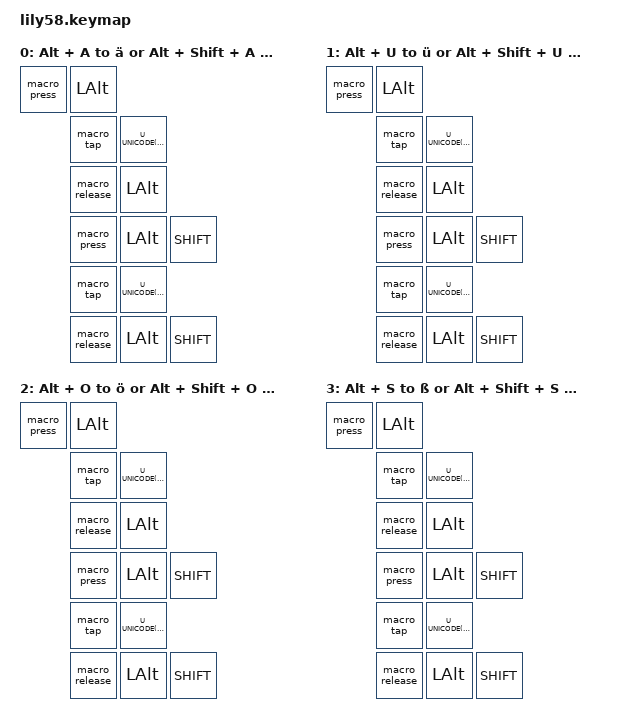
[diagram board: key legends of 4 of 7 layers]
/*
 * Copyright (c) 2020 The ZMK Contributors
 *
 * SPDX-License-Identifier: MIT
 */

#include <behaviors.dtsi>
#include <dt-bindings/zmk/keys.h>
#include <dt-bindings/zmk/bt.h>
#include <dt-bindings/zmk/ext_power.h>

/ {
    keymap {
        compatible = "zmk,keymap";

// Makro-Definition hier:
        a_alt_macro {
            label = "Alt + A to ä or Alt + Shift + A to Ä";
            compatible = "zmk,behavior-macro";
            wait-ms = <40>;
            tap-ms = <40>;
            bindings
                // Wenn nur Alt gedrückt wird
                = <&macro_press   &kp LALT>  
                , <&macro_tap     &kp U_UNICODE(0x00E4)>  // Unicode für kleines ä (Alt + A)
                , <&macro_release &kp LALT>

                // Wenn Alt + Shift gedrückt werden
                , <&macro_press   &kp LALT &kp SHIFT>
                , <&macro_tap     &kp U_UNICODE(0x00C4)>  // Unicode für großes Ä (Alt + Shift + A)
                , <&macro_release &kp LALT &kp SHIFT>;
        };

        // Makro für Alt + U (ü) und Alt + Shift + U (Ü)
        u_alt_macro {
            label = "Alt + U to ü or Alt + Shift + U to Ü";
            compatible = "zmk,behavior-macro";
            wait-ms = <40>;
            tap-ms = <40>;
            bindings
                // Wenn nur Alt gedrückt wird
                = <&macro_press   &kp LALT>  
                , <&macro_tap     &kp U_UNICODE(0x00FC)>  // Unicode für kleines ü (Alt + U)
                , <&macro_release &kp LALT>

                // Wenn Alt + Shift gedrückt werden
                , <&macro_press   &kp LALT &kp SHIFT>
                , <&macro_tap     &kp U_UNICODE(0x00DC)>  // Unicode für großes Ü (Alt + Shift + U)
                , <&macro_release &kp LALT &kp SHIFT>;
        };

        // Makro für Alt + O (ö) und Alt + Shift + O (Ö)
        o_alt_macro {
            label = "Alt + O to ö or Alt + Shift + O to Ö";
            compatible = "zmk,behavior-macro";
            wait-ms = <40>;
            tap-ms = <40>;
            bindings
                // Wenn nur Alt gedrückt wird
                = <&macro_press   &kp LALT>  
                , <&macro_tap     &kp U_UNICODE(0x00F6)>  // Unicode für kleines ö (Alt + O)
                , <&macro_release &kp LALT>

                // Wenn Alt + Shift gedrückt werden
                , <&macro_press   &kp LALT &kp SHIFT>
                , <&macro_tap     &kp U_UNICODE(0x00D6)>  // Unicode für großes Ö (Alt + Shift + O)
                , <&macro_release &kp LALT &kp SHIFT>;
        };

        // Makro für Alt + S (ß) und Alt + Shift + S (ẞ)
        s_alt_macro {
            label = "Alt + S to ß or Alt + Shift + S to ẞ";
            compatible = "zmk,behavior-macro";
            wait-ms = <40>;
            tap-ms = <40>;
            bindings
                // Wenn nur Alt gedrückt wird
                = <&macro_press   &kp LALT>  
                , <&macro_tap     &kp U_UNICODE(0x00DF)>  // Unicode für ß (Alt + S)
                , <&macro_release &kp LALT>

                // Wenn Alt + Shift gedrückt werden
                , <&macro_press   &kp LALT &kp SHIFT>
                , <&macro_tap     &kp U_UNICODE(0x1E9E)>  // Unicode für großes ẞ (Alt + Shift + S)
                , <&macro_release &kp LALT &kp SHIFT>;
        };

        default_layer {
            // ------------------------------------------------------------------------------------------------------------
            // |  ESC  |  1  |  2  |  3   |  4   |  5   |                   |  6   |  7    |  8    |  9   |   0   |   `   |
            // |  TAB  |  Q  |  W  |  E   |  R   |  T   |                   |  Y   |  U    |  I    |  O   |   P   |   -   |
            // |  CTRL |  A  |  S  |  D   |  F   |  G   |                   |  H   |  J    |  K    |  L   |   ;   |   '   |
            // | SHIFT |  Z  |  X  |  C   |  V   |  B   |   "["  |  |  "]"  |  N   |  M    |  ,    |  .   |   /   | SHIFT |
            //                     | ALT  | GUI  | LOWER|  SPACE |  | ENTER | RAISE| BSPC  | GUI   |

            bindings = <
&kp ESCAPE  &kp N1  &kp N2  &kp N3    &kp N4    &kp N5                          &kp N6         &kp N7  &kp N8     &kp N9   &kp N0     &none
&kp TAB     &kp Q   &kp W   &kp E     &kp R     &kp T                           &kp Z          &u_alt_macro  &kp I       &o_alt_macro   &kp P      &kp PLUS
&kp LCTRL   &a_alt_macro   &s_alt_macro  &kp D     &kp F     &kp G                           &kp H          &kp J   &kp K      &kp L    &kp SEMI   &kp HASH
&kp LSHFT   &kp Y   &kp X   &kp C     &kp V     &kp B   &kp LBKT     &kp RBKT   &kp N          &kp M   &kp COMMA  &kp DOT  &kp MINUS  &kp RALT
                            &kp LALT  &kp LGUI  &mo 1   &kp ENTER    &kp SPACE  &kp BACKSPACE  &mo 2   &kp RGUI
            >;

            sensor-bindings = <&inc_dec_kp C_VOL_UP C_VOL_DN>;
        };

        lower_layer {
            // ------------------------------------------------------------------------------------------------------------
            // | BTCLR | BT1 | BT2 |  BT3 |  BT4 |  BT5 |                   |      |       |       |      |       |       |
            // |  F1   |  F2 |  F3 |  F4  |  F5  |  F6  |                   |  F7  |  F8   |  F9   |  F10 |  F11  |  F12  |
            // |   `   |  !  |  @  |  #   |  $   |  %   |                   |  ^   |  &    |  *    |  (   |   )   |   ~   |
            // |       |     |     |      |      |      |        |  |       |      |  _    |  +    |  {   |   }   |  "|"  |
            //                     |      |      |      |        |  |       |      |       |       |

            bindings = <
&trans  &kp EXCLAMATION  &kp DOUBLE_QUOTES  &kp LS(KP_NUMBER_3)  &kp DOLLAR       &kp PERCENT                        &kp AMPERSAND  &kp SLASH      &kp LEFT_PARENTHESIS  &kp RIGHT_PARENTHESIS  &kp EQUAL          &kp QUESTION
&trans  &kp EXCLAMATION  &kp DOUBLE_QUOTES  &kp LS(KP_NUMBER_3)  &kp DOLLAR       &kp PERCENT                        &kp AMPERSAND  &kp SLASH      &kp LEFT_PARENTHESIS  &kp RIGHT_PARENTHESIS  &kp EQUAL          &kp QUESTION
&trans  &kp KP_NUMBER_1  &kp KP_NUMBER_2    &kp KP_NUMBER_3      &kp KP_NUMBER_4  &kp KP_NUMBER_5                    &none          &kp BSLH       &none                 &kp LEFT_BRACKET       &kp RIGHT_BRACKET  &kp PIPE
&trans  &kp KP_NUMBER_6  &kp KP_NUMBER_7    &kp KP_NUMBER_8      &kp KP_NUMBER_9  &kp KP_NUMBER_0  &none     &none   &kp TILDE      &kp SEMICOLON  &kp UNDERSCORE        &kp LBRC               &kp RBRC           &kp PIPE
                                            &trans               &trans           &trans           &trans    &trans  &trans         &trans         &trans
            >;

            sensor-bindings = <&inc_dec_kp C_VOL_UP C_VOL_DN>;
        };

        raise_layer {
            // ------------------------------------------------------------------------------------------------------------
            // |       |     |     |      |      |      |                   |      |       |       |      |       |       |
            // |   `   |  1  |  2  |  3   |  4   |  5   |                   |  6   |   7   |   8   |  9   |   0   |       |
            // |   F1  |  F2 |  F3 |  F4  |  F5  |  F6  |                   |      |   <-  |   v   |  ^   |  ->   |       |
            // |   F7  |  F8 |  F9 |  F10 |  F11 |  F12 |        |  |       |  +   |   -   |   =   |  [   |   ]   |   \   |
            //                     |      |      |      |        |  |       |      |       |       |

            bindings = <
&none       &none           &none         &none         &none         &none                               &none     &none     &none   &none      &none    &none
&none       &kp F1          &kp F2        &kp F3        &kp F4        &kp F5                              &kp F6    &kp F7    &kp N8  &kp N9     &kp F10  &none
&none       &kp C_PREVIOUS  &kp C_NEXT    &kp C_VOL_DN  &kp C_VOL_UP  &kp C_PLAY_PAUSE                    &kp LEFT  &kp DOWN  &kp UP  &kp RIGHT  &none    &none
&bt BT_CLR  &bt BT_SEL 0    &bt BT_SEL 1  &bt BT_SEL 2  &bt BT_SEL 3  &bt BT_SEL 4      &none     &none   &none     &none     &none   &none      &none    &none
                                          &trans        &trans        &trans            &trans    &trans  &trans    &trans    &trans
            >;
        };
    };
};
